# Spinlock register map
Vendor: Texas Instruments
Peripheral module from a debugger description file (folder am571x).
Registers are 32-bit, access per field, reset 0x0 unless marked. A register's access mark holds for its fields unless they carry their own. Offsets are as the file gives them; lines under a group give offsets from that group; [hi:lo] are bit positions; {n}, {i} and the like mark numbered series; 'fields as' and 'values as' point back to an identical list; <NAME> marks a mode.

## Spinlock
0x00 SPINLOCK_REVISION ro reset not defined — This register contains the IP revision code
  [31:0] REVISION — IP revision
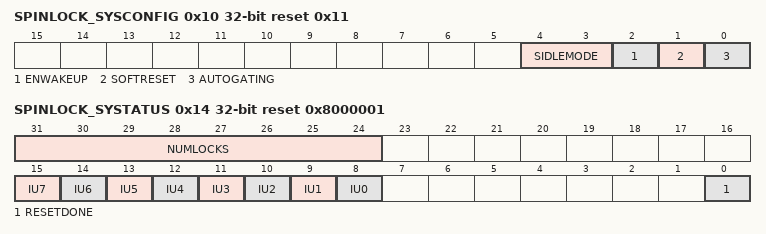
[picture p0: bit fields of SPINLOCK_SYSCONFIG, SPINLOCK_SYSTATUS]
0x10 SPINLOCK_SYSCONFIG reset 0x11 — This register controls the various parameters of the OCP interface. Note that most fields are read-only.
  [4:3] SIDLEMODE ro — Slave interface power management (IDLE request/acknowledgement control).
    0=IDLE_0 (Force-idle. IDLE request is acknowledged unconditionally and immediately.); 1=IDLE_1 (No-idle. IDLE request is never acknowledged.); 2=IDLE_2 (Smart-idle. IDLE request acknowledgement is based on the internal module activity.); 3=Reserved._Do_not_use
  [2] ENWAKEUP ro — Asynchronous wakeup gereration.
    0=NOWAKEUPGEN (Wakeup generation is disabled.); 1=WAKEUPGEN (Wakeup generation is enabled.)
  [1] SOFTRESET wo — Module software reset.
    0=NOOP (No action); 1=DORESET (Start soft reset sequence)
  [0] AUTOGATING ro — Internal interface clock gating strategy.
    0=FREERUNNING (Interface clock is not gated when the interface is idle.); 1=GATED (Automatic internal OCP clock gating strategy is applied, based on the OCP interface activity.)
0x14 SPINLOCK_SYSTATUS ro reset 0x8000001 — This register provides status information about this instance of the Spinlock module.
  [31:24] NUMLOCKS — Number of lock registers implemeted.
    1=This_instance_has_32_lock_registers; 2=This_instance_has_64_lock_registers; 4=This_instance_has_128_lock_registers; 8=This_instance_has_256_lock_registers
  [n+8] IU{n} (n=0..7) — In-Use flag 0, covering lock registers {32n} - {32n+31}.
    0=IU{n}_0_r (All lock registers {32n} - {32n+31} are in the Not Taken state.); 1=IU{n}_1_r (At least one of the lock registers {32n} - {32n+31} is in the Taken state.)
  [0] RESETDONE — Reset done status.
    0=Reset_in_progress; 1=Reset_is_completed
{0x800+4i} SPINLOCK_LOCK_REG_i_{i} (i=0..255) — This register contains the state of one lock.
  [0] TAKEN rw — Lock State
    0=FREE (Lock was previously Not Taken (free). The requester is granted the lock.); 0=FREE (Set the lock to Not Taken (free).); 1=BUSY (Lock was previously Taken. The requester is not granted the lock and must retry.); 1=BUSY (No update to the lock value.)
